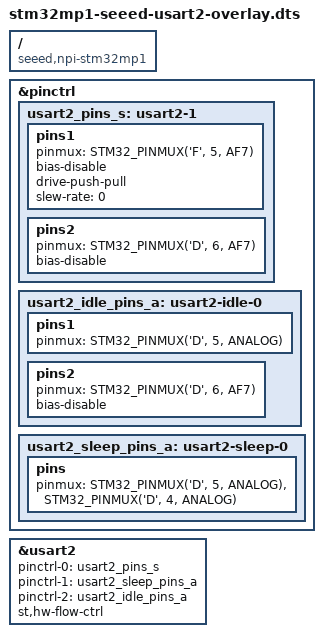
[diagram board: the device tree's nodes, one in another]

/*
 * Device tree overlay for usart2
 */


#include "dt-bindings/gpio/gpio.h"
#include "dt-bindings/pinctrl/stm32-pinfunc.h"

/dts-v1/;
/plugin/;

/ {
     compatible = "seeed,npi-stm32mp1", "st,stm32mp157";
    fragment@0 {
        target = <&pinctrl>;
        __overlay__ {
			usart2_pins_s: usart2-1 {
				pins1 {
					pinmux = <STM32_PINMUX('F', 5, AF7)>;/* USART2_TX */
						//  <STM32_PINMUX('D', 4, AF7)>; /* USART2_RTS */
					bias-disable;
					drive-push-pull;
					slew-rate = <0>;
				};
				pins2 {
					pinmux = <STM32_PINMUX('D', 6, AF7)>; /* USART2_RX */
						//  <STM32_PINMUX('E',15, AF7)>; /* USART2_CTS_NSS */
					bias-disable;
				};
			};

			usart2_idle_pins_a: usart2-idle-0 {
				pins1 {
					pinmux = <STM32_PINMUX('D', 5, ANALOG)>; /* USART2_TX */
						//  <STM32_PINMUX('D', 4, ANALOG)>, /* USART2_RTS */
						//  <STM32_PINMUX('D', 3, ANALOG)>; /* USART2_CTS_NSS */
				};
				pins2 {
					pinmux = <STM32_PINMUX('D', 6, AF7)>; /* USART2_RX */
					bias-disable;
				};
			};

			usart2_sleep_pins_a: usart2-sleep-0 {
				pins {
					pinmux = <STM32_PINMUX('D', 5, ANALOG)>, /* USART2_TX */
						 <STM32_PINMUX('D', 4, ANALOG)>;/* USART2_RTS */
						//  <STM32_PINMUX('D', 6, ANALOG)>, /* USART2_RX */
						//  <STM32_PINMUX('D', 3, ANALOG)>; /* USART2_CTS_NSS */
				};
			};

        };
    };
    fragment@1 {
        target = <&usart2>;
        __overlay__ {
            pinctrl-names = "default", "sleep", "idle";
            pinctrl-0 = <&usart2_pins_s>;
            pinctrl-1 = <&usart2_sleep_pins_a>;
            pinctrl-2 = <&usart2_idle_pins_a>;
            st,hw-flow-ctrl;
            status = "okay";
        };
    };
};

